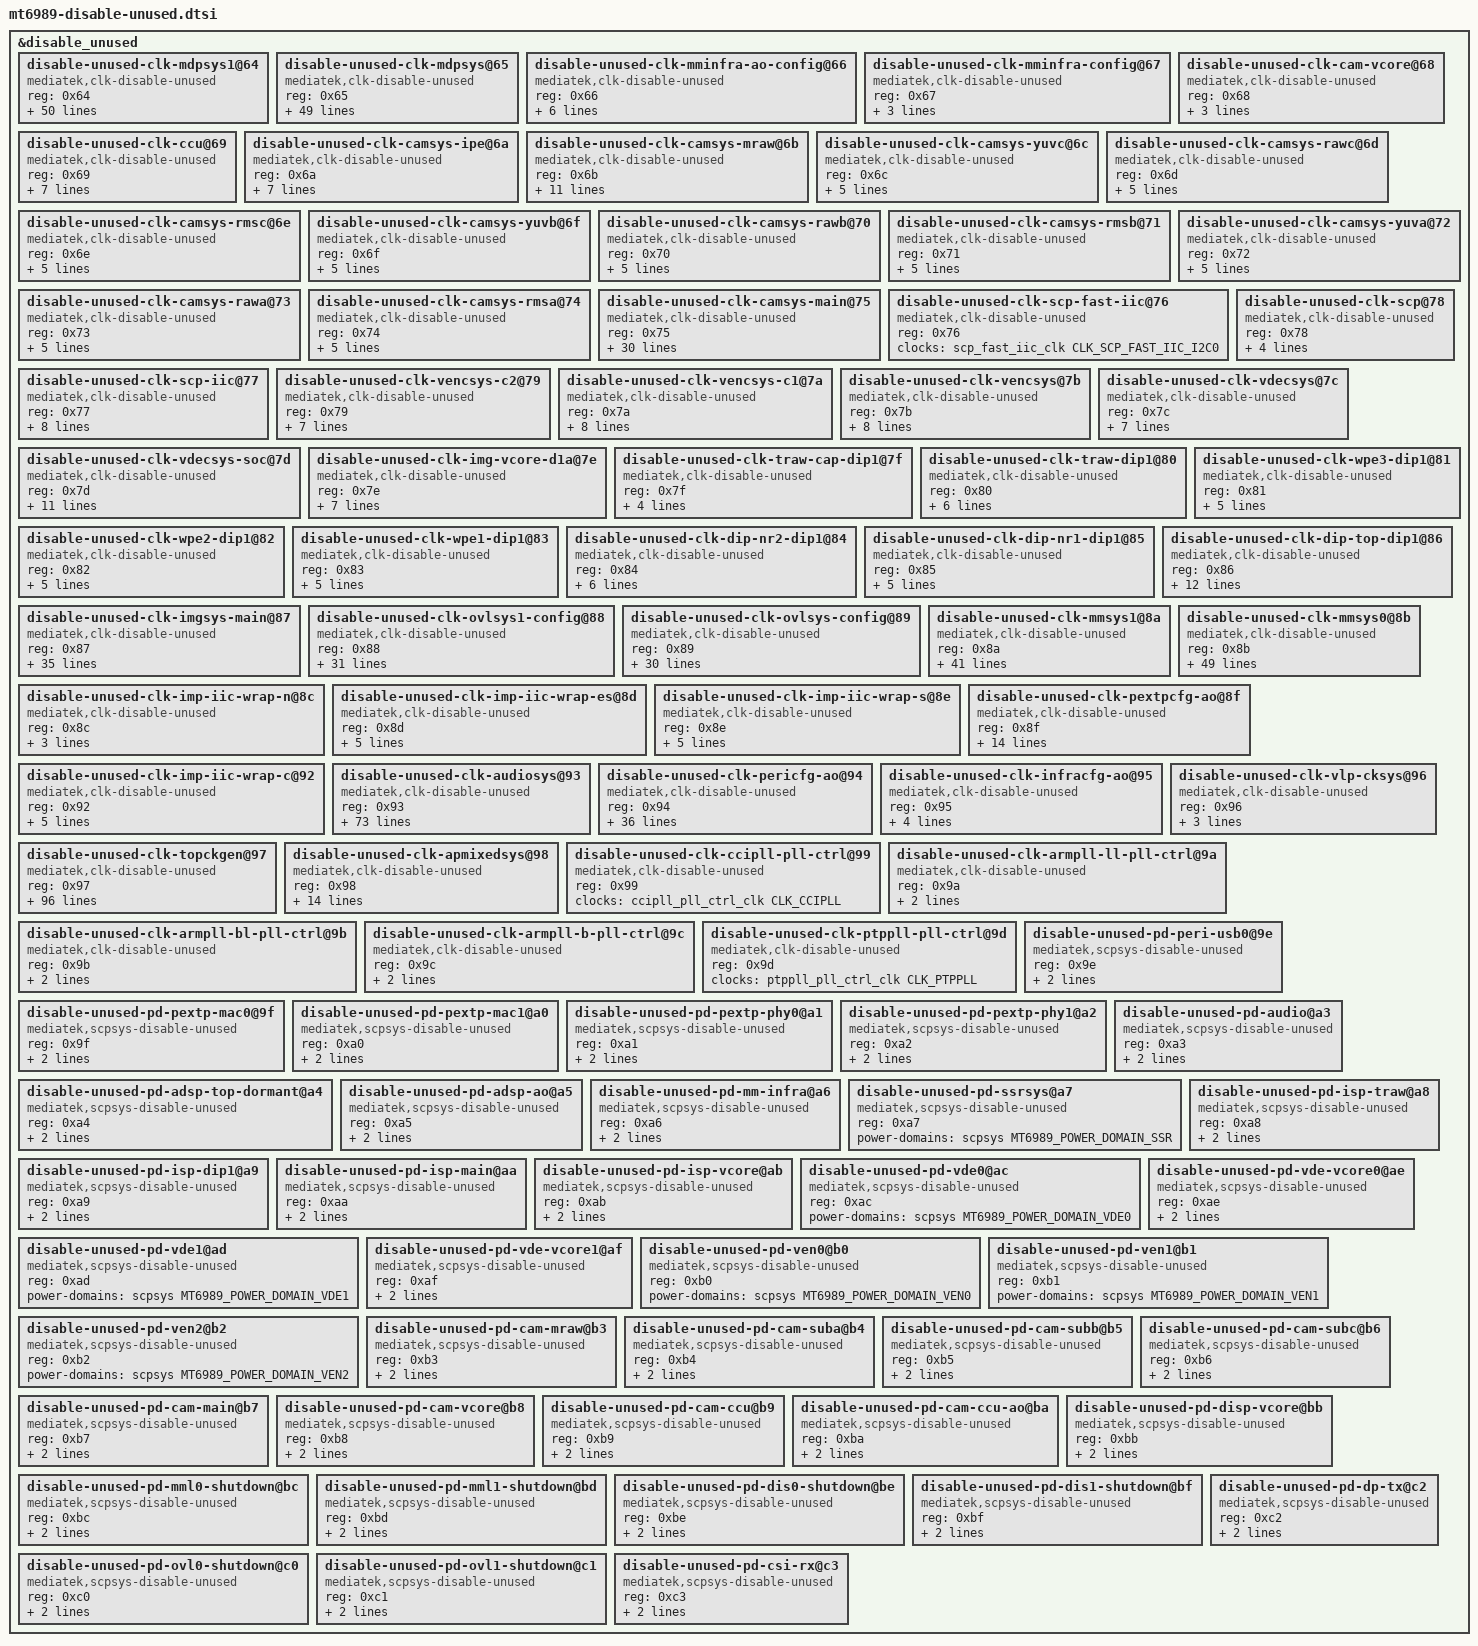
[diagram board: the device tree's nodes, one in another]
// SPDX-License-Identifier: (GPL-2.0 OR MIT)
/*
 * Copyright (C) 2023 MediaTek Inc.
 * Author: Owen Chen <owen.chen@mediatek.com>
 */

&disable_unused {
	status = "okay";
	disable-unused-clk-mdpsys1@64 {
		compatible = "mediatek,clk-disable-unused";
		reg = <0x64>;
		clocks =
			<&mdpsys1_config_clk CLK_MDP1_MDP_MUTEX0>,
			<&mdpsys1_config_clk CLK_MDP1_APB_BUS>,
			<&mdpsys1_config_clk CLK_MDP1_SMI0>,
			<&mdpsys1_config_clk CLK_MDP1_MDP_RDMA0>,
			<&mdpsys1_config_clk CLK_MDP1_MDP_RDMA2>,
			<&mdpsys1_config_clk CLK_MDP1_MDP_HDR0>,
			<&mdpsys1_config_clk CLK_MDP1_MDP_AAL0>,
			<&mdpsys1_config_clk CLK_MDP1_MDP_RSZ0>,
			<&mdpsys1_config_clk CLK_MDP1_MDP_TDSHP0>,
			<&mdpsys1_config_clk CLK_MDP1_MDP_COLOR0>,
			<&mdpsys1_config_clk CLK_MDP1_MDP_WROT0>,
			<&mdpsys1_config_clk CLK_MDP1_MDP_FAKE_ENG0>,
			<&mdpsys1_config_clk CLK_MDP1_MDP_DLI_ASYNC0>,
			<&mdpsys1_config_clk CLK_MDP1_MDP_DLI_ASYNC1>,
			<&mdpsys1_config_clk CLK_MDP1_APB_DB>,
			<&mdpsys1_config_clk CLK_MDP1_MDP_RDMA1>,
			<&mdpsys1_config_clk CLK_MDP1_MDP_RDMA3>,
			<&mdpsys1_config_clk CLK_MDP1_MDP_HDR1>,
			<&mdpsys1_config_clk CLK_MDP1_MDP_AAL1>,
			<&mdpsys1_config_clk CLK_MDP1_MDP_RSZ1>,
			<&mdpsys1_config_clk CLK_MDP1_MDP_TDSHP1>,
			<&mdpsys1_config_clk CLK_MDP1_MDP_COLOR1>,
			<&mdpsys1_config_clk CLK_MDP1_MDP_WROT1>,
			<&mdpsys1_config_clk CLK_MDP1_MDP_RSZ2>,
			<&mdpsys1_config_clk CLK_MDP1_MDP_WROT2>,
			<&mdpsys1_config_clk CLK_MDP1_MDP_DLO_ASYNC0>,
			<&mdpsys1_config_clk CLK_MDP1_MDP_RSZ3>,
			<&mdpsys1_config_clk CLK_MDP1_MDP_WROT3>,
			<&mdpsys1_config_clk CLK_MDP1_MDP_DLO_ASYNC1>,
			<&mdpsys1_config_clk CLK_MDP1_MDP_DLI_ASYNC2>,
			<&mdpsys1_config_clk CLK_MDP1_MDP_DLI_ASYNC3>,
			<&mdpsys1_config_clk CLK_MDP1_MDP_DLO_ASYNC2>,
			<&mdpsys1_config_clk CLK_MDP1_MDP_DLO_ASYNC3>,
			<&mdpsys1_config_clk CLK_MDP1_MDP_BIRSZ0>,
			<&mdpsys1_config_clk CLK_MDP1_MDP_BIRSZ1>,
			<&mdpsys1_config_clk CLK_MDP1_IMG_DL_ASYNC0>,
			<&mdpsys1_config_clk CLK_MDP1_IMG_DL_ASYNC1>,
			<&mdpsys1_config_clk CLK_MDP1_HRE_TOP_MDPSYS>,
			<&mdpsys1_config_clk CLK_MDP1_MDP_RROT0>,
			<&mdpsys1_config_clk CLK_MDP1_MDP_RROT0_2ND>,
			<&mdpsys1_config_clk CLK_MDP1_MDP_MERGE0>,
			<&mdpsys1_config_clk CLK_MDP1_MDP_C3D0>,
			<&mdpsys1_config_clk CLK_MDP1_MDP_FG0>,
			<&mdpsys1_config_clk CLK_MDP1_IMG_DL_RELAY0>,
			<&mdpsys1_config_clk CLK_MDP1_F26M_SLOW>,
			<&mdpsys1_config_clk CLK_MDP1_F32K_SLOW>,
			<&mdpsys1_config_clk CLK_MDP1_IMG_DL_RELAY1>;
		power-domains = <&scpsys MT6989_POWER_DOMAIN_MML1_SHUTDOWN>;
	};

	disable-unused-clk-mdpsys@65 {
		compatible = "mediatek,clk-disable-unused";
		reg = <0x65>;
		clocks =
			<&mdpsys_config_clk CLK_MDP_MUTEX0>,
			<&mdpsys_config_clk CLK_MDP_APB_BUS>,
			<&mdpsys_config_clk CLK_MDP_SMI0>,
			<&mdpsys_config_clk CLK_MDP_RDMA0>,
			<&mdpsys_config_clk CLK_MDP_RDMA2>,
			<&mdpsys_config_clk CLK_MDP_HDR0>,
			<&mdpsys_config_clk CLK_MDP_AAL0>,
			<&mdpsys_config_clk CLK_MDP_RSZ0>,
			<&mdpsys_config_clk CLK_MDP_TDSHP0>,
			<&mdpsys_config_clk CLK_MDP_COLOR0>,
			<&mdpsys_config_clk CLK_MDP_WROT0>,
			<&mdpsys_config_clk CLK_MDP_FAKE_ENG0>,
			<&mdpsys_config_clk CLK_MDP_DLI_ASYNC0>,
			<&mdpsys_config_clk CLK_MDP_DLI_ASYNC1>,
			<&mdpsys_config_clk CLK_MDP_APB_DB>,
			<&mdpsys_config_clk CLK_MDP_RDMA1>,
			<&mdpsys_config_clk CLK_MDP_RDMA3>,
			<&mdpsys_config_clk CLK_MDP_HDR1>,
			<&mdpsys_config_clk CLK_MDP_AAL1>,
			<&mdpsys_config_clk CLK_MDP_RSZ1>,
			<&mdpsys_config_clk CLK_MDP_TDSHP1>,
			<&mdpsys_config_clk CLK_MDP_COLOR1>,
			<&mdpsys_config_clk CLK_MDP_WROT1>,
			<&mdpsys_config_clk CLK_MDP_RSZ2>,
			<&mdpsys_config_clk CLK_MDP_WROT2>,
			<&mdpsys_config_clk CLK_MDP_DLO_ASYNC0>,
			<&mdpsys_config_clk CLK_MDP_RSZ3>,
			<&mdpsys_config_clk CLK_MDP_WROT3>,
			<&mdpsys_config_clk CLK_MDP_DLO_ASYNC1>,
			<&mdpsys_config_clk CLK_MDP_DLI_ASYNC2>,
			<&mdpsys_config_clk CLK_MDP_DLI_ASYNC3>,
			<&mdpsys_config_clk CLK_MDP_DLO_ASYNC2>,
			<&mdpsys_config_clk CLK_MDP_DLO_ASYNC3>,
			<&mdpsys_config_clk CLK_MDP_BIRSZ0>,
			<&mdpsys_config_clk CLK_MDP_BIRSZ1>,
			<&mdpsys_config_clk CLK_MDP_IMG_DL_ASYNC0>,
			<&mdpsys_config_clk CLK_MDP_IMG_DL_ASYNC1>,
			<&mdpsys_config_clk CLK_MDP_HRE_TOP_MDPSYS>,
			<&mdpsys_config_clk CLK_MDP_RROT0>,
			<&mdpsys_config_clk CLK_MDP_RROT0_2ND>,
			<&mdpsys_config_clk CLK_MDP_MERGE0>,
			<&mdpsys_config_clk CLK_MDP_C3D0>,
			<&mdpsys_config_clk CLK_MDP_FG0>,
			<&mdpsys_config_clk CLK_MDP_IMG_DL_RELAY0>,
			<&mdpsys_config_clk CLK_MDP_F26M_SLOW>,
			<&mdpsys_config_clk CLK_MDP_F32K_SLOW>,
			<&mdpsys_config_clk CLK_MDP_IMG_DL_RELAY1>;
		power-domains = <&scpsys MT6989_POWER_DOMAIN_MML0_SHUTDOWN>;
	};

	disable-unused-clk-mminfra-ao-config@66 {
		compatible = "mediatek,clk-disable-unused";
		reg = <0x66>;
		clocks =
			<&mminfra_ao_config_clk CLK_MMINFRA_AO_GCE_D>,
			<&mminfra_ao_config_clk CLK_MMINFRA_AO_GCE_M>,
			<&mminfra_ao_config_clk CLK_MMINFRA_AO_GCE_26M>;
		power-domains = <&scpsys MT6989_POWER_DOMAIN_MM_INFRA>;
	};

	disable-unused-clk-mminfra-config@67 {
		compatible = "mediatek,clk-disable-unused";
		reg = <0x67>;
		clocks =
			<&mminfra_config_clk CLK_MMINFRA_SMI>;
		power-domains = <&scpsys MT6989_POWER_DOMAIN_MM_INFRA>;
	};

	disable-unused-clk-cam-vcore@68 {
		compatible = "mediatek,clk-disable-unused";
		reg = <0x68>;
		clocks =
			<&cam_vcore_clk CLK_CAM_V_MM0_SUBCOMM>;
		power-domains = <&scpsys MT6989_POWER_DOMAIN_CAM_MAIN>;
	};

	disable-unused-clk-ccu@69 {
		compatible = "mediatek,clk-disable-unused";
		reg = <0x69>;
		clocks =
			<&ccu_main_clk CLK_CCU_LARB30_CON>,
			<&ccu_main_clk CLK_CCU_AHB_CON>,
			<&ccu_main_clk CLK_CCUSYS_CCU0_CON>,
			<&ccu_main_clk CLK_CCUSYS_CCU1_CON>,
			<&ccu_main_clk CLK_CCU2MM0_GALS_CON>;
		power-domains = <&scpsys MT6989_POWER_DOMAIN_CAM_CCU>;
	};

	disable-unused-clk-camsys-ipe@6a {
		compatible = "mediatek,clk-disable-unused";
		reg = <0x6a>;
		clocks =
			<&camsys_ipe_clk CLK_CAMSYS_IPE_LARB19>,
			<&camsys_ipe_clk CLK_CAMSYS_IPE_DPE>,
			<&camsys_ipe_clk CLK_CAMSYS_IPE_FUS>,
			<&camsys_ipe_clk CLK_CAMSYS_IPE_DHZE>,
			<&camsys_ipe_clk CLK_CAMSYS_IPE_GALS>;
		power-domains = <&scpsys MT6989_POWER_DOMAIN_CAM_MRAW>;
	};

	disable-unused-clk-camsys-mraw@6b {
		compatible = "mediatek,clk-disable-unused";
		reg = <0x6b>;
		clocks =
			<&camsys_mraw_clk CLK_CAM_MR_LARBX>,
			<&camsys_mraw_clk CLK_CAM_MR_GALS>,
			<&camsys_mraw_clk CLK_CAM_MR_CAMTG>,
			<&camsys_mraw_clk CLK_CAM_MR_MRAW0>,
			<&camsys_mraw_clk CLK_CAM_MR_MRAW1>,
			<&camsys_mraw_clk CLK_CAM_MR_MRAW2>,
			<&camsys_mraw_clk CLK_CAM_MR_MRAW3>,
			<&camsys_mraw_clk CLK_CAM_MR_PDA0>,
			<&camsys_mraw_clk CLK_CAM_MR_PDA1>;
		power-domains = <&scpsys MT6989_POWER_DOMAIN_CAM_MRAW>;
	};

	disable-unused-clk-camsys-yuvc@6c {
		compatible = "mediatek,clk-disable-unused";
		reg = <0x6c>;
		clocks =
			<&camsys_yuvc_clk CLK_CAM_YC_LARBX>,
			<&camsys_yuvc_clk CLK_CAM_YC_CAM>,
			<&camsys_yuvc_clk CLK_CAM_YC_CAMTG>;
		power-domains = <&scpsys MT6989_POWER_DOMAIN_CAM_SUBC>;
	};

	disable-unused-clk-camsys-rawc@6d {
		compatible = "mediatek,clk-disable-unused";
		reg = <0x6d>;
		clocks =
			<&camsys_rawc_clk CLK_CAM_RC_LARBX>,
			<&camsys_rawc_clk CLK_CAM_RC_CAM>,
			<&camsys_rawc_clk CLK_CAM_RC_CAMTG>;
		power-domains = <&scpsys MT6989_POWER_DOMAIN_CAM_SUBC>;
	};

	disable-unused-clk-camsys-rmsc@6e {
		compatible = "mediatek,clk-disable-unused";
		reg = <0x6e>;
		clocks =
			<&camsys_rmsc_clk CLK_CAMSYS_RMSC_LARBX>,
			<&camsys_rmsc_clk CLK_CAMSYS_RMSC_CAM>,
			<&camsys_rmsc_clk CLK_CAMSYS_RMSC_CAMTG>;
		power-domains = <&scpsys MT6989_POWER_DOMAIN_CAM_SUBC>;
	};

	disable-unused-clk-camsys-yuvb@6f {
		compatible = "mediatek,clk-disable-unused";
		reg = <0x6f>;
		clocks =
			<&camsys_yuvb_clk CLK_CAM_YB_LARBX>,
			<&camsys_yuvb_clk CLK_CAM_YB_CAM>,
			<&camsys_yuvb_clk CLK_CAM_YB_CAMTG>;
		power-domains = <&scpsys MT6989_POWER_DOMAIN_CAM_SUBB>;
	};

	disable-unused-clk-camsys-rawb@70 {
		compatible = "mediatek,clk-disable-unused";
		reg = <0x70>;
		clocks =
			<&camsys_rawb_clk CLK_CAM_RB_LARBX>,
			<&camsys_rawb_clk CLK_CAM_RB_CAM>,
			<&camsys_rawb_clk CLK_CAM_RB_CAMTG>;
		power-domains = <&scpsys MT6989_POWER_DOMAIN_CAM_SUBB>;
	};

	disable-unused-clk-camsys-rmsb@71 {
		compatible = "mediatek,clk-disable-unused";
		reg = <0x71>;
		clocks =
			<&camsys_rmsb_clk CLK_CAMSYS_RMSB_LARBX>,
			<&camsys_rmsb_clk CLK_CAMSYS_RMSB_CAM>,
			<&camsys_rmsb_clk CLK_CAMSYS_RMSB_CAMTG>;
		power-domains = <&scpsys MT6989_POWER_DOMAIN_CAM_SUBB>;
	};

	disable-unused-clk-camsys-yuva@72 {
		compatible = "mediatek,clk-disable-unused";
		reg = <0x72>;
		clocks =
			<&camsys_yuva_clk CLK_CAM_YA_LARBX>,
			<&camsys_yuva_clk CLK_CAM_YA_CAM>,
			<&camsys_yuva_clk CLK_CAM_YA_CAMTG>;
		power-domains = <&scpsys MT6989_POWER_DOMAIN_CAM_SUBA>;
	};

	disable-unused-clk-camsys-rawa@73 {
		compatible = "mediatek,clk-disable-unused";
		reg = <0x73>;
		clocks =
			<&camsys_rawa_clk CLK_CAM_RA_LARBX>,
			<&camsys_rawa_clk CLK_CAM_RA_CAM>,
			<&camsys_rawa_clk CLK_CAM_RA_CAMTG>;
		power-domains = <&scpsys MT6989_POWER_DOMAIN_CAM_SUBA>;
	};

	disable-unused-clk-camsys-rmsa@74 {
		compatible = "mediatek,clk-disable-unused";
		reg = <0x74>;
		clocks =
			<&camsys_rmsa_clk CLK_CAMSYS_RMSA_LARBX>,
			<&camsys_rmsa_clk CLK_CAMSYS_RMSA_CAM>,
			<&camsys_rmsa_clk CLK_CAMSYS_RMSA_CAMTG>;
		power-domains = <&scpsys MT6989_POWER_DOMAIN_CAM_SUBA>;
	};

	disable-unused-clk-camsys-main@75 {
		compatible = "mediatek,clk-disable-unused";
		reg = <0x75>;
		clocks =
			<&camsys_main_clk CLK_CAM_MAIN_LARB13>,
			<&camsys_main_clk CLK_CAM_MAIN_LARB14>,
			<&camsys_main_clk CLK_CAM_MAIN_LARB27>,
			<&camsys_main_clk CLK_CAM_MAIN_LARB29>,
			<&camsys_main_clk CLK_CAM_MAIN_CAM>,
			<&camsys_main_clk CLK_CAM_MAIN_CAM_SUBA>,
			<&camsys_main_clk CLK_CAM_MAIN_CAM_SUBB>,
			<&camsys_main_clk CLK_CAM_MAIN_CAM_SUBC>,
			<&camsys_main_clk CLK_CAM_MAIN_CAM_MRAW>,
			<&camsys_main_clk CLK_CAM_MAIN_CAMTG>,
			<&camsys_main_clk CLK_CAM_MAIN_SENINF>,
			<&camsys_main_clk CLK_CAM_MAIN_CAMSV_TOP>,
			<&camsys_main_clk CLK_CAM_MAIN_ADLRD>,
			<&camsys_main_clk CLK_CAM_MAIN_ADLWR>,
			<&camsys_main_clk CLK_CAM_MAIN_UISP>,
			<&camsys_main_clk CLK_CAM_MAIN_CAM2MM0_GALS>,
			<&camsys_main_clk CLK_CAM_MAIN_CAM2MM1_GALS>,
			<&camsys_main_clk CLK_CAM_MAIN_CAM2SYS_GALS>,
			<&camsys_main_clk CLK_CAM_MAIN_CAM2MM2_GALS>,
			<&camsys_main_clk CLK_CAM_MAIN_CCUSYS>,
			<&camsys_main_clk CLK_CAM_MAIN_CAM_DPE>,
			<&camsys_main_clk CLK_CAM_MAIN_CAM_ASG>,
			<&camsys_main_clk CLK_CAM_MAIN_CAMSV_A_CON_1>,
			<&camsys_main_clk CLK_CAM_MAIN_CAMSV_B_CON_1>,
			<&camsys_main_clk CLK_CAM_MAIN_CAMSV_C_CON_1>,
			<&camsys_main_clk CLK_CAM_MAIN_CAMSV_D_CON_1>,
			<&camsys_main_clk CLK_CAM_MAIN_CAMSV_E_CON_1>,
			<&camsys_main_clk CLK_CAM_MAIN_CAMSV_CON_1>;
		power-domains = <&scpsys MT6989_POWER_DOMAIN_CAM_MAIN>;
	};

	disable-unused-clk-scp-fast-iic@76 {
		compatible = "mediatek,clk-disable-unused";
		reg = <0x76>;
		clocks =
			<&scp_fast_iic_clk CLK_SCP_FAST_IIC_I2C0>;
	};

	disable-unused-clk-scp-iic@77 {
		compatible = "mediatek,clk-disable-unused";
		reg = <0x77>;
		clocks =
			<&scp_iic_clk CLK_SCP_IIC_I2C0>,
			<&scp_iic_clk CLK_SCP_IIC_I2C1>,
			<&scp_iic_clk CLK_SCP_IIC_I2C2>,
			<&scp_iic_clk CLK_SCP_IIC_I2C3>,
			<&scp_iic_clk CLK_SCP_IIC_I2C4>,
			<&scp_iic_clk CLK_SCP_IIC_I2C5>,
			<&scp_iic_clk CLK_SCP_IIC_I2C6>,
			<&scp_iic_clk CLK_SCP_IIC_I2C7>;
	};

	disable-unused-clk-scp@78 {
		compatible = "mediatek,clk-disable-unused";
		reg = <0x78>;
		clocks =
			<&scp_clk CLK_SCP_SET_SPI0>,
			<&scp_clk CLK_SCP_SET_SPI1>,
			<&scp_clk CLK_SCP_SET_SPI2>,
			<&scp_clk CLK_SCP_SET_SPI3>;
	};

	disable-unused-clk-vencsys-c2@79 {
		compatible = "mediatek,clk-disable-unused";
		reg = <0x79>;
		clocks =
			<&venc_gcon_core2_clk CLK_VEN_C2_CKE0_LARB>,
			<&venc_gcon_core2_clk CLK_VEN_C2_CKE1_VENC>,
			<&venc_gcon_core2_clk CLK_VEN_C2_CKE2_JPGENC>,
			<&venc_gcon_core2_clk CLK_VEN_C2_CKE5_GALS>,
			<&venc_gcon_core2_clk CLK_VEN_C2_CKE6_GALS_SRAM>;
		power-domains = <&scpsys MT6989_POWER_DOMAIN_VEN2>;
	};

	disable-unused-clk-vencsys-c1@7a {
		compatible = "mediatek,clk-disable-unused";
		reg = <0x7a>;
		clocks =
			<&venc_gcon_core1_clk CLK_VEN2_CKE0_LARB>,
			<&venc_gcon_core1_clk CLK_VEN2_CKE1_VENC>,
			<&venc_gcon_core1_clk CLK_VEN2_CKE2_JPGENC>,
			<&venc_gcon_core1_clk CLK_VEN2_CKE3_JPGDEC>,
			<&venc_gcon_core1_clk CLK_VEN2_CKE5_GALS>,
			<&venc_gcon_core1_clk CLK_VEN2_CKE6_GALS_SRAM>;
		power-domains = <&scpsys MT6989_POWER_DOMAIN_VEN1>;
	};

	disable-unused-clk-vencsys@7b {
		compatible = "mediatek,clk-disable-unused";
		reg = <0x7b>;
		clocks =
			<&venc_gcon_clk CLK_VEN1_CKE0_LARB>,
			<&venc_gcon_clk CLK_VEN1_CKE1_VENC>,
			<&venc_gcon_clk CLK_VEN1_CKE2_JPGENC>,
			<&venc_gcon_clk CLK_VEN1_CKE3_JPGDEC>,
			<&venc_gcon_clk CLK_VEN1_CKE4_JPGDEC_C1>,
			<&venc_gcon_clk CLK_VEN1_CKE5_GALS>,
			<&venc_gcon_clk CLK_VEN1_CKE6_GALS_SRAM>;
		power-domains = <&scpsys MT6989_POWER_DOMAIN_VEN0>;
	};

	disable-unused-clk-vdecsys@7c {
		compatible = "mediatek,clk-disable-unused";
		reg = <0x7c>;
		clocks =
			<&vdec_gcon_base_clk CLK_VDE2_LAT_CKEN>,
			<&vdec_gcon_base_clk CLK_VDE2_LAT_ACTIVE>,
			<&vdec_gcon_base_clk CLK_VDE2_LAT_CKEN_ENG>,
			<&vdec_gcon_base_clk CLK_VDE2_VDEC_CKEN>,
			<&vdec_gcon_base_clk CLK_VDE2_VDEC_ACTIVE>,
			<&vdec_gcon_base_clk CLK_VDE2_VDEC_CKEN_ENG>;
		power-domains = <&scpsys MT6989_POWER_DOMAIN_VDE1>;
	};

	disable-unused-clk-vdecsys-soc@7d {
		compatible = "mediatek,clk-disable-unused";
		reg = <0x7d>;
		clocks =
			<&vdec_soc_gcon_base_clk CLK_VDE1_LAT_CKEN>,
			<&vdec_soc_gcon_base_clk CLK_VDE1_LAT_ACTIVE>,
			<&vdec_soc_gcon_base_clk CLK_VDE1_LAT_CKEN_ENG>,
			<&vdec_soc_gcon_base_clk CLK_VDE1_VDEC_CKEN>,
			<&vdec_soc_gcon_base_clk CLK_VDE1_VDEC_ACTIVE>,
			<&vdec_soc_gcon_base_clk CLK_VDE1_VDEC_CKEN_ENG>,
			<&vdec_soc_gcon_base_clk CLK_VDE1_VDEC_SOC_APTV_EN>,
			<&vdec_soc_gcon_base_clk CLK_VDE1_VDEC_SOC_APTV_TOP_EN>,
			<&vdec_soc_gcon_base_clk CLK_VDE1_VDEC_SOC_IPS_EN>;
		power-domains = <&scpsys MT6989_POWER_DOMAIN_VDE0>;
	};

	disable-unused-clk-img-vcore-d1a@7e {
		compatible = "mediatek,clk-disable-unused";
		reg = <0x7e>;
		clocks =
			<&img_vcore_d1a_clk CLK_IMG_VCORE_GALS_DISP>,
			<&img_vcore_d1a_clk CLK_IMG_VCORE_MAIN>,
			<&img_vcore_d1a_clk CLK_IMG_VCORE_SUB0>,
			<&img_vcore_d1a_clk CLK_IMG_VCORE_SUB1>;
		power-domains = <&scpsys MT6989_POWER_DOMAIN_ISP_MAIN>;
	};

	disable-unused-clk-traw-cap-dip1@7f {
		compatible = "mediatek,clk-disable-unused";
		reg = <0x7f>;
		clocks =
			<&traw_cap_dip1_clk CLK_TRAW_CAP_DIP1_TRAW_CAP>;
		power-domains = <&scpsys MT6989_POWER_DOMAIN_ISP_DIP1>;
	};

	disable-unused-clk-traw-dip1@80 {
		compatible = "mediatek,clk-disable-unused";
		reg = <0x80>;
		clocks =
			<&traw_dip1_clk CLK_TRAW_DIP1_LARB28>,
			<&traw_dip1_clk CLK_TRAW_DIP1_LARB40>,
			<&traw_dip1_clk CLK_TRAW_DIP1_TRAW>,
			<&traw_dip1_clk CLK_TRAW_DIP1_GALS>;
		power-domains = <&scpsys MT6989_POWER_DOMAIN_ISP_DIP1>;
	};

	disable-unused-clk-wpe3-dip1@81 {
		compatible = "mediatek,clk-disable-unused";
		reg = <0x81>;
		clocks =
			<&wpe3_dip1_clk CLK_WPE3_DIP1_LARB11>,
			<&wpe3_dip1_clk CLK_WPE3_DIP1_WPE>,
			<&wpe3_dip1_clk CLK_WPE3_DIP1_GALS0>;
		power-domains = <&scpsys MT6989_POWER_DOMAIN_ISP_DIP1>;
	};

	disable-unused-clk-wpe2-dip1@82 {
		compatible = "mediatek,clk-disable-unused";
		reg = <0x82>;
		clocks =
			<&wpe2_dip1_clk CLK_WPE2_DIP1_LARB11>,
			<&wpe2_dip1_clk CLK_WPE2_DIP1_WPE>,
			<&wpe2_dip1_clk CLK_WPE2_DIP1_GALS0>;
		power-domains = <&scpsys MT6989_POWER_DOMAIN_ISP_DIP1>;
	};

	disable-unused-clk-wpe1-dip1@83 {
		compatible = "mediatek,clk-disable-unused";
		reg = <0x83>;
		clocks =
			<&wpe1_dip1_clk CLK_WPE1_DIP1_LARB11>,
			<&wpe1_dip1_clk CLK_WPE1_DIP1_WPE>,
			<&wpe1_dip1_clk CLK_WPE1_DIP1_GALS0>;
		power-domains = <&scpsys MT6989_POWER_DOMAIN_ISP_DIP1>;
	};

	disable-unused-clk-dip-nr2-dip1@84 {
		compatible = "mediatek,clk-disable-unused";
		reg = <0x84>;
		clocks =
			<&dip_nr2_dip1_clk CLK_DIP_NR2_DIP1_LARB15>,
			<&dip_nr2_dip1_clk CLK_DIP_NR2_DIP1_DIP_NR>,
			<&dip_nr2_dip1_clk CLK_DIP_NR2_DIP1_LARB39>;
		power-domains = <&scpsys MT6989_POWER_DOMAIN_ISP_DIP1>;
	};

	disable-unused-clk-dip-nr1-dip1@85 {
		compatible = "mediatek,clk-disable-unused";
		reg = <0x85>;
		clocks =
			<&dip_nr1_dip1_clk CLK_DIP_NR1_DIP1_LARB>,
			<&dip_nr1_dip1_clk CLK_DIP_NR1_DIP1_DIP_NR1>;
		power-domains = <&scpsys MT6989_POWER_DOMAIN_ISP_DIP1>;
	};

	disable-unused-clk-dip-top-dip1@86 {
		compatible = "mediatek,clk-disable-unused";
		reg = <0x86>;
		clocks =
			<&dip_top_dip1_clk CLK_DIP_TOP_DIP1_DIP_TOP>,
			<&dip_top_dip1_clk CLK_DIP_TOP_DIP1_DIP_TOP_GALS0>,
			<&dip_top_dip1_clk CLK_DIP_TOP_DIP1_DIP_TOP_GALS1>,
			<&dip_top_dip1_clk CLK_DIP_TOP_DIP1_DIP_TOP_GALS2>,
			<&dip_top_dip1_clk CLK_DIP_TOP_DIP1_DIP_TOP_GALS3>,
			<&dip_top_dip1_clk CLK_DIP_TOP_DIP1_LARB10>,
			<&dip_top_dip1_clk CLK_DIP_TOP_DIP1_LARB15>,
			<&dip_top_dip1_clk CLK_DIP_TOP_DIP1_LARB38>,
			<&dip_top_dip1_clk CLK_DIP_TOP_DIP1_LARB39>;
		power-domains = <&scpsys MT6989_POWER_DOMAIN_ISP_DIP1>;
	};

	disable-unused-clk-imgsys-main@87 {
		compatible = "mediatek,clk-disable-unused";
		reg = <0x87>;
		clocks =
			<&imgsys_main_clk CLK_IMG_FDVT>,
			<&imgsys_main_clk CLK_IMG_ME>,
			<&imgsys_main_clk CLK_IMG_MMG>,
			<&imgsys_main_clk CLK_IMG_LARB12>,
			<&imgsys_main_clk CLK_IMG_LARB9>,
			<&imgsys_main_clk CLK_IMG_TRAW0>,
			<&imgsys_main_clk CLK_IMG_TRAW1>,
			<&imgsys_main_clk CLK_IMG_DIP0>,
			<&imgsys_main_clk CLK_IMG_WPE0>,
			<&imgsys_main_clk CLK_IMG_IPE>,
			<&imgsys_main_clk CLK_IMG_WPE1>,
			<&imgsys_main_clk CLK_IMG_WPE2>,
			<&imgsys_main_clk CLK_IMG_ADL_LARB>,
			<&imgsys_main_clk CLK_IMG_ADLRD>,
			<&imgsys_main_clk CLK_IMG_ADLWR>,
			<&imgsys_main_clk CLK_IMG_AVS>,
			<&imgsys_main_clk CLK_IMG_IPS>,
			<&imgsys_main_clk CLK_IMG_SUB_COMMON0>,
			<&imgsys_main_clk CLK_IMG_SUB_COMMON1>,
			<&imgsys_main_clk CLK_IMG_SUB_COMMON2>,
			<&imgsys_main_clk CLK_IMG_SUB_COMMON3>,
			<&imgsys_main_clk CLK_IMG_SUB_COMMON4>,
			<&imgsys_main_clk CLK_IMG_GALS_RX_DIP0>,
			<&imgsys_main_clk CLK_IMG_GALS_RX_DIP1>,
			<&imgsys_main_clk CLK_IMG_GALS_RX_TRAW0>,
			<&imgsys_main_clk CLK_IMG_GALS_RX_WPE0>,
			<&imgsys_main_clk CLK_IMG_GALS_RX_WPE1>,
			<&imgsys_main_clk CLK_IMG_GALS_RX_WPE2>,
			<&imgsys_main_clk CLK_IMG_GALS_RX_IPE0>,
			<&imgsys_main_clk CLK_IMG_GALS_TX_IPE0>,
			<&imgsys_main_clk CLK_IMG_GALS_RX_IPE1>,
			<&imgsys_main_clk CLK_IMG_GALS_TX_IPE1>,
			<&imgsys_main_clk CLK_IMG_GALS>;
		power-domains = <&scpsys MT6989_POWER_DOMAIN_ISP_MAIN>;
	};

	disable-unused-clk-ovlsys1-config@88 {
		compatible = "mediatek,clk-disable-unused";
		reg = <0x88>;
		clocks =
			<&ovlsys1_config_clk CLK_OVL1_OVLSYS_CONFIG>,
			<&ovlsys1_config_clk CLK_OVL1_DISP_FAKE_ENG0>,
			<&ovlsys1_config_clk CLK_OVL1_DISP_FAKE_ENG1>,
			<&ovlsys1_config_clk CLK_OVL1_DISP_MUTEX0>,
			<&ovlsys1_config_clk CLK_OVL1_DISP_OVL0_2L>,
			<&ovlsys1_config_clk CLK_OVL1_DISP_OVL1_2L>,
			<&ovlsys1_config_clk CLK_OVL1_DISP_OVL2_2L>,
			<&ovlsys1_config_clk CLK_OVL1_DISP_OVL3_2L>,
			<&ovlsys1_config_clk CLK_OVL1_DISP_RSZ1>,
			<&ovlsys1_config_clk CLK_OVL1_MDP_RSZ0>,
			<&ovlsys1_config_clk CLK_OVL1_DISP_WDMA0>,
			<&ovlsys1_config_clk CLK_OVL1_DISP_UFBC_WDMA0>,
			<&ovlsys1_config_clk CLK_OVL1_DISP_WDMA2>,
			<&ovlsys1_config_clk CLK_OVL1_DISP_DLI_ASYNC0>,
			<&ovlsys1_config_clk CLK_OVL1_DISP_DLI_ASYNC1>,
			<&ovlsys1_config_clk CLK_OVL1_DISP_DLI_ASYNC2>,
			<&ovlsys1_config_clk CLK_OVL1_DISP_DL0_ASYNC0>,
			<&ovlsys1_config_clk CLK_OVL1_DISP_DL0_ASYNC1>,
			<&ovlsys1_config_clk CLK_OVL1_DISP_DL0_ASYNC2>,
			<&ovlsys1_config_clk CLK_OVL1_DISP_DL0_ASYNC3>,
			<&ovlsys1_config_clk CLK_OVL1_DISP_DL0_ASYNC4>,
			<&ovlsys1_config_clk CLK_OVL1_DISP_DL0_ASYNC5>,
			<&ovlsys1_config_clk CLK_OVL1_DISP_DL0_ASYNC6>,
			<&ovlsys1_config_clk CLK_OVL1_INLINEROT0>,
			<&ovlsys1_config_clk CLK_OVL1_SMI_SUB_COMM0>,
			<&ovlsys1_config_clk CLK_OVL1_DISP_Y2R0>,
			<&ovlsys1_config_clk CLK_OVL1_DISP_Y2R1>,
			<&ovlsys1_config_clk CLK_OVL1_DISP_OVL4_2L>;
		power-domains = <&scpsys MT6989_POWER_DOMAIN_OVL1_SHUTDOWN>;
	};

	disable-unused-clk-ovlsys-config@89 {
		compatible = "mediatek,clk-disable-unused";
		reg = <0x89>;
		clocks =
			<&ovlsys_config_clk CLK_OVLSYS_CONFIG>,
			<&ovlsys_config_clk CLK_OVL_DISP_FAKE_ENG0>,
			<&ovlsys_config_clk CLK_OVL_DISP_FAKE_ENG1>,
			<&ovlsys_config_clk CLK_OVL_DISP_MUTEX0>,
			<&ovlsys_config_clk CLK_OVL_DISP_OVL0_2L>,
			<&ovlsys_config_clk CLK_OVL_DISP_OVL1_2L>,
			<&ovlsys_config_clk CLK_OVL_DISP_OVL2_2L>,
			<&ovlsys_config_clk CLK_OVL_DISP_OVL3_2L>,
			<&ovlsys_config_clk CLK_OVL_DISP_RSZ1>,
			<&ovlsys_config_clk CLK_OVL_MDP_RSZ0>,
			<&ovlsys_config_clk CLK_OVL_DISP_WDMA0>,
			<&ovlsys_config_clk CLK_OVL_DISP_UFBC_WDMA0>,
			<&ovlsys_config_clk CLK_OVL_DISP_WDMA2>,
			<&ovlsys_config_clk CLK_OVL_DISP_DLI_ASYNC0>,
			<&ovlsys_config_clk CLK_OVL_DISP_DLI_ASYNC1>,
			<&ovlsys_config_clk CLK_OVL_DISP_DLI_ASYNC2>,
			<&ovlsys_config_clk CLK_OVL_DISP_DL0_ASYNC0>,
			<&ovlsys_config_clk CLK_OVL_DISP_DL0_ASYNC1>,
			<&ovlsys_config_clk CLK_OVL_DISP_DL0_ASYNC2>,
			<&ovlsys_config_clk CLK_OVL_DISP_DL0_ASYNC3>,
			<&ovlsys_config_clk CLK_OVL_DISP_DL0_ASYNC4>,
			<&ovlsys_config_clk CLK_OVL_DISP_DL0_ASYNC5>,
			<&ovlsys_config_clk CLK_OVL_DISP_DL0_ASYNC6>,
			<&ovlsys_config_clk CLK_OVL_INLINEROT0>,
			<&ovlsys_config_clk CLK_OVL_SMI_SUB_COMM0>,
			<&ovlsys_config_clk CLK_OVL_DISP_Y2R0>,
			<&ovlsys_config_clk CLK_OVL_DISP_Y2R1>,
			<&ovlsys_config_clk CLK_OVL_DISP_OVL4_2L>;
		power-domains = <&scpsys MT6989_POWER_DOMAIN_OVL0_SHUTDOWN>;
	};

	disable-unused-clk-mmsys1@8a {
		compatible = "mediatek,clk-disable-unused";
		reg = <0x8a>;
		clocks =
			<&dispsys1_config_clk CLK_MM1_DISPSYS1_CONFIG>,
			<&dispsys1_config_clk CLK_MM1_DISP_MUTEX0>,
			<&dispsys1_config_clk CLK_MM1_DISP_DLI_ASYNC0>,
			<&dispsys1_config_clk CLK_MM1_DISP_DLI_ASYNC1>,
			<&dispsys1_config_clk CLK_MM1_DISP_DLI_ASYNC2>,
			<&dispsys1_config_clk CLK_MM1_MDP_RDMA0>,
			<&dispsys1_config_clk CLK_MM1_DISP_R2Y0>,
			<&dispsys1_config_clk CLK_MM1_DISP_SPLITTER0>,
			<&dispsys1_config_clk CLK_MM1_DISP_SPLITTER1>,
			<&dispsys1_config_clk CLK_MM1_DISP_VDCM0>,
			<&dispsys1_config_clk CLK_MM1_DISP_DSC_WRAP0>,
			<&dispsys1_config_clk CLK_MM1_DISP_DSC_WRAP1>,
			<&dispsys1_config_clk CLK_MM1_DISP_DSC_WRAP2>,
			<&dispsys1_config_clk CLK_MM1_DISP_DP_INTF0>,
			<&dispsys1_config_clk CLK_MM1_DISP_DSI0>,
			<&dispsys1_config_clk CLK_MM1_DISP_DSI1>,
			<&dispsys1_config_clk CLK_MM1_DISP_DSI2>,
			<&dispsys1_config_clk CLK_MM1_DISP_MERGE0>,
			<&dispsys1_config_clk CLK_MM1_DISP_WDMA0>,
			<&dispsys1_config_clk CLK_MM1_SMI_SUB_COMM0>,
			<&dispsys1_config_clk CLK_MM1_DISP_WDMA1>,
			<&dispsys1_config_clk CLK_MM1_DISP_WDMA2>,
			<&dispsys1_config_clk CLK_MM1_DISP_GDMA0>,
			<&dispsys1_config_clk CLK_MM1_DISP_DLI_ASYNC3>,
			<&dispsys1_config_clk CLK_MM1_DISP_DLI_ASYNC4>,
			<&dispsys1_config_clk CLK_MM1_MOD1>,
			<&dispsys1_config_clk CLK_MM1_MOD2>,
			<&dispsys1_config_clk CLK_MM1_MOD3>,
			<&dispsys1_config_clk CLK_MM1_MOD4>,
			<&dispsys1_config_clk CLK_MM1_MOD5>,
			<&dispsys1_config_clk CLK_MM1_MOD6>,
			<&dispsys1_config_clk CLK_MM1_MOD7>,
			<&dispsys1_config_clk CLK_MM1_SUBSYS>,
			<&dispsys1_config_clk CLK_MM1_DSI0>,
			<&dispsys1_config_clk CLK_MM1_DSI1>,
			<&dispsys1_config_clk CLK_MM1_DSI2>,
			<&dispsys1_config_clk CLK_MM1_DP>,
			<&dispsys1_config_clk CLK_MM1_F26M>;
		power-domains = <&scpsys MT6989_POWER_DOMAIN_DIS1_SHUTDOWN>;
	};

	disable-unused-clk-mmsys0@8b {
		compatible = "mediatek,clk-disable-unused";
		reg = <0x8b>;
		clocks =
			<&dispsys_config_clk CLK_MM_CONFIG>,
			<&dispsys_config_clk CLK_MM_DISP_MUTEX0>,
			<&dispsys_config_clk CLK_MM_DISP_AAL0>,
			<&dispsys_config_clk CLK_MM_DISP_AAL1>,
			<&dispsys_config_clk CLK_MM_DISP_C3D0>,
			<&dispsys_config_clk CLK_MM_DISP_C3D1>,
			<&dispsys_config_clk CLK_MM_DISP_CCORR0>,
			<&dispsys_config_clk CLK_MM_DISP_CCORR1>,
			<&dispsys_config_clk CLK_MM_DISP_CCORR2>,
			<&dispsys_config_clk CLK_MM_DISP_CCORR3>,
			<&dispsys_config_clk CLK_MM_DISP_CHIST0>,
			<&dispsys_config_clk CLK_MM_DISP_CHIST1>,
			<&dispsys_config_clk CLK_MM_DISP_COLOR0>,
			<&dispsys_config_clk CLK_MM_DISP_COLOR1>,
			<&dispsys_config_clk CLK_MM_DISP_DITHER0>,
			<&dispsys_config_clk CLK_MM_DISP_DITHER1>,
			<&dispsys_config_clk CLK_MM_DISP_DITHER2>,
			<&dispsys_config_clk CLK_MM_DLI_ASYNC0>,
			<&dispsys_config_clk CLK_MM_DLI_ASYNC1>,
			<&dispsys_config_clk CLK_MM_DLI_ASYNC2>,
			<&dispsys_config_clk CLK_MM_DLI_ASYNC3>,
			<&dispsys_config_clk CLK_MM_DLI_ASYNC4>,
			<&dispsys_config_clk CLK_MM_DLI_ASYNC5>,
			<&dispsys_config_clk CLK_MM_DLI_ASYNC6>,
			<&dispsys_config_clk CLK_MM_DLI_ASYNC7>,
			<&dispsys_config_clk CLK_MM_DLO_ASYNC0>,
			<&dispsys_config_clk CLK_MM_DLO_ASYNC1>,
			<&dispsys_config_clk CLK_MM_DLO_ASYNC2>,
			<&dispsys_config_clk CLK_MM_DLO_ASYNC3>,
			<&dispsys_config_clk CLK_MM_DLO_ASYNC4>,
			<&dispsys_config_clk CLK_MM_DISP_GAMMA0>,
			<&dispsys_config_clk CLK_MM_DISP_GAMMA1>,
			<&dispsys_config_clk CLK_MM_MDP_AAL0>,
			<&dispsys_config_clk CLK_MM_MDP_RDMA0>,
			<&dispsys_config_clk CLK_MM_DISP_ODDMR0>,
			<&dispsys_config_clk CLK_MM_DISP_POSTALIGN0>,
			<&dispsys_config_clk CLK_MM_DISP_POSTMASK0>,
			<&dispsys_config_clk CLK_MM_DISP_POSTMASK1>,
			<&dispsys_config_clk CLK_MM_DISP_RSZ0>,
			<&dispsys_config_clk CLK_MM_DISP_RSZ1>,
			<&dispsys_config_clk CLK_MM_DISP_SPR0>,
			<&dispsys_config_clk CLK_MM_DISP_TDSHP0>,
			<&dispsys_config_clk CLK_MM_DISP_TDSHP1>,
			<&dispsys_config_clk CLK_MM_DISP_WDMA1>,
			<&dispsys_config_clk CLK_MM_DISP_Y2R0>,
			<&dispsys_config_clk CLK_MM_MDP_AAL1>,
			<&dispsys_config_clk CLK_MM_SMI_SUB_COMM0>;
		power-domains = <&scpsys MT6989_POWER_DOMAIN_DIS0_SHUTDOWN>;
	};

	disable-unused-clk-imp-iic-wrap-n@8c {
		compatible = "mediatek,clk-disable-unused";
		reg = <0x8c>;
		clocks =
			<&imp_iic_wrap_n_clk CLK_IMPN_I2C0>,
			<&imp_iic_wrap_n_clk CLK_IMPN_I2C6>,
			<&imp_iic_wrap_n_clk CLK_IMPN_SEC_EN>;
	};

	disable-unused-clk-imp-iic-wrap-es@8d {
		compatible = "mediatek,clk-disable-unused";
		reg = <0x8d>;
		clocks =
			<&imp_iic_wrap_es_clk CLK_IMPES_I2C2>,
			<&imp_iic_wrap_es_clk CLK_IMPES_I2C4>,
			<&imp_iic_wrap_es_clk CLK_IMPES_I2C7>,
			<&imp_iic_wrap_es_clk CLK_IMPES_I2C8>,
			<&imp_iic_wrap_es_clk CLK_IMPES_SEC_EN>;
	};

	disable-unused-clk-imp-iic-wrap-s@8e {
		compatible = "mediatek,clk-disable-unused";
		reg = <0x8e>;
		clocks =
			<&imp_iic_wrap_s_clk CLK_IMPS_I2C1>,
			<&imp_iic_wrap_s_clk CLK_IMPS_I2C3>,
			<&imp_iic_wrap_s_clk CLK_IMPS_I2C5>,
			<&imp_iic_wrap_s_clk CLK_IMPS_I2C9>,
			<&imp_iic_wrap_s_clk CLK_IMPS_SEC_EN>;
	};

	disable-unused-clk-pextpcfg-ao@8f {
		compatible = "mediatek,clk-disable-unused";
		reg = <0x8f>;
		clocks =
			<&pextpcfg_ao_clk CLK_PEXTP_P0_MAC_REF>,
			<&pextpcfg_ao_clk CLK_PEXTP_P0_MAC_PL_P>,
			<&pextpcfg_ao_clk CLK_PEXTP_P0_MAC_TL>,
			<&pextpcfg_ao_clk CLK_PEXTP_P0_MAC_AXI>,
			<&pextpcfg_ao_clk CLK_PEXTP_P0_MAC_AHB_APB>,
			<&pextpcfg_ao_clk CLK_PEXTP_P0_PHY_REF>,
			<&pextpcfg_ao_clk CLK_PEXTP_P0_PHY_MCU_BUS>,
			<&pextpcfg_ao_clk CLK_PEXTP_P1_MAC_REF>,
			<&pextpcfg_ao_clk CLK_PEXTP_P1_MAC_PL_P>,
			<&pextpcfg_ao_clk CLK_PEXTP_P1_MAC_TL>,
			<&pextpcfg_ao_clk CLK_PEXTP_P1_MAC_AXI>,
			<&pextpcfg_ao_clk CLK_PEXTP_P1_MAC_AHB_APB>,
			<&pextpcfg_ao_clk CLK_PEXTP_P1_PHY_REF>,
			<&pextpcfg_ao_clk CLK_PEXTP_P1_PHY_MCU_BUS>;
	};

	disable-unused-clk-imp-iic-wrap-c@92 {
		compatible = "mediatek,clk-disable-unused";
		reg = <0x92>;
		clocks =
			<&imp_iic_wrap_c_clk CLK_IMPC_I2C10>,
			<&imp_iic_wrap_c_clk CLK_IMPC_I2C11>,
			<&imp_iic_wrap_c_clk CLK_IMPC_I2C12>,
			<&imp_iic_wrap_c_clk CLK_IMPC_I2C13>,
			<&imp_iic_wrap_c_clk CLK_IMPC_SEC_EN>;
	};

	disable-unused-clk-audiosys@93 {
		compatible = "mediatek,clk-disable-unused";
		reg = <0x93>;
		clocks =
			<&afe_clk CLK_AFE_MEMIF_INTBUS_CLK>,
			<&afe_clk CLK_AFE_MEMIF_HOP_CLK>,
			<&afe_clk CLK_AFE_PCM1>,
			<&afe_clk CLK_AFE_PCM0>,
			<&afe_clk CLK_AFE_SOUNDWIRE>,
			<&afe_clk CLK_AFE_CM1>,
			<&afe_clk CLK_AFE_CM0>,
			<&afe_clk CLK_AFE_STF>,
			<&afe_clk CLK_AFE_HW_GAIN23>,
			<&afe_clk CLK_AFE_HW_GAIN01>,
			<&afe_clk CLK_AFE_DAIBT>,
			<&afe_clk CLK_AFE_MERGE_IF>,
			<&afe_clk CLK_AFE_FM_I2S>,
			<&afe_clk CLK_AFE_UL2_ADC_HIRES_TML>,
			<&afe_clk CLK_AFE_UL2_ADC_HIRES>,
			<&afe_clk CLK_AFE_UL2_TML>,
			<&afe_clk CLK_AFE_UL2_ADC>,
			<&afe_clk CLK_AFE_UL1_ADC_HIRES_TML>,
			<&afe_clk CLK_AFE_UL1_ADC_HIRES>,
			<&afe_clk CLK_AFE_UL1_TML>,
			<&afe_clk CLK_AFE_UL1_ADC>,
			<&afe_clk CLK_AFE_UL0_ADC_HIRES_TML>,
			<&afe_clk CLK_AFE_UL0_ADC_HIRES>,
			<&afe_clk CLK_AFE_UL0_TML>,
			<&afe_clk CLK_AFE_UL0_ADC>,
			<&afe_clk CLK_AFE_DPRX>,
			<&afe_clk CLK_AFE_DPTX>,
			<&afe_clk CLK_AFE_ETDM_IN6>,
			<&afe_clk CLK_AFE_ETDM_IN5>,
			<&afe_clk CLK_AFE_ETDM_IN4>,
			<&afe_clk CLK_AFE_ETDM_IN3>,
			<&afe_clk CLK_AFE_ETDM_IN2>,
			<&afe_clk CLK_AFE_ETDM_IN1>,
			<&afe_clk CLK_AFE_ETDM_IN0>,
			<&afe_clk CLK_AFE_ETDM_OUT6>,
			<&afe_clk CLK_AFE_ETDM_OUT5>,
			<&afe_clk CLK_AFE_ETDM_OUT4>,
			<&afe_clk CLK_AFE_ETDM_OUT3>,
			<&afe_clk CLK_AFE_ETDM_OUT2>,
			<&afe_clk CLK_AFE_ETDM_OUT1>,
			<&afe_clk CLK_AFE_ETDM_OUT0>,
			<&afe_clk CLK_AFE_GENERAL24_ASRC>,
			<&afe_clk CLK_AFE_GENERAL23_ASRC>,
			<&afe_clk CLK_AFE_GENERAL22_ASRC>,
			<&afe_clk CLK_AFE_GENERAL21_ASRC>,
			<&afe_clk CLK_AFE_GENERAL20_ASRC>,
			<&afe_clk CLK_AFE_GENERAL19_ASRC>,
			<&afe_clk CLK_AFE_GENERAL18_ASRC>,
			<&afe_clk CLK_AFE_GENERAL17_ASRC>,
			<&afe_clk CLK_AFE_GENERAL16_ASRC>,
			<&afe_clk CLK_AFE_GENERAL15_ASRC>,
			<&afe_clk CLK_AFE_GENERAL14_ASRC>,
			<&afe_clk CLK_AFE_GENERAL13_ASRC>,
			<&afe_clk CLK_AFE_GENERAL12_ASRC>,
			<&afe_clk CLK_AFE_GENERAL11_ASRC>,
			<&afe_clk CLK_AFE_GENERAL10_ASRC>,
			<&afe_clk CLK_AFE_GENERAL9_ASRC>,
			<&afe_clk CLK_AFE_GENERAL8_ASRC>,
			<&afe_clk CLK_AFE_GENERAL7_ASRC>,
			<&afe_clk CLK_AFE_GENERAL6_ASRC>,
			<&afe_clk CLK_AFE_GENERAL5_ASRC>,
			<&afe_clk CLK_AFE_GENERAL4_ASRC>,
			<&afe_clk CLK_AFE_GENERAL3_ASRC>,
			<&afe_clk CLK_AFE_GENERAL2_ASRC>,
			<&afe_clk CLK_AFE_GENERAL1_ASRC>,
			<&afe_clk CLK_AFE_GENERAL0_ASRC>,
			<&afe_clk CLK_AFE_CONNSYS_I2S_ASRC>,
			<&afe_clk CLK_AFE_AUDIO_HOPPING>,
			<&afe_clk CLK_AFE_AUDIO_F26M>,
			<&afe_clk CLK_AFE_APLL1>,
			<&afe_clk CLK_AFE_APLL2>,
			<&afe_clk CLK_AFE_H208M>,
			<&afe_clk CLK_AFE_APLL_TUNER2>,
			<&afe_clk CLK_AFE_APLL_TUNER1>;
		power-domains = <&scpsys MT6989_POWER_DOMAIN_AUDIO>;
	};

	disable-unused-clk-pericfg-ao@94 {
		compatible = "mediatek,clk-disable-unused";
		reg = <0x94>;
		clocks =
			<&pericfg_ao_clk CLK_PERAOP_UART0>,
			<&pericfg_ao_clk CLK_PERAOP_UART1>,
			<&pericfg_ao_clk CLK_PERAOP_UART2>,
			<&pericfg_ao_clk CLK_PERAOP_UART3>,
			<&pericfg_ao_clk CLK_PERAOP_PWM_H>,
			<&pericfg_ao_clk CLK_PERAOP_PWM_B>,
			<&pericfg_ao_clk CLK_PERAOP_PWM_FB1>,
			<&pericfg_ao_clk CLK_PERAOP_PWM_FB2>,
			<&pericfg_ao_clk CLK_PERAOP_PWM_FB3>,
			<&pericfg_ao_clk CLK_PERAOP_PWM_FB4>,
			<&pericfg_ao_clk CLK_PERAOP_DISP_PWM0>,
			<&pericfg_ao_clk CLK_PERAOP_DISP_PWM1>,
			<&pericfg_ao_clk CLK_PERAOP_SPI0_B>,
			<&pericfg_ao_clk CLK_PERAOP_SPI1_B>,
			<&pericfg_ao_clk CLK_PERAOP_SPI2_B>,
			<&pericfg_ao_clk CLK_PERAOP_SPI3_B>,
			<&pericfg_ao_clk CLK_PERAOP_SPI4_B>,
			<&pericfg_ao_clk CLK_PERAOP_SPI5_B>,
			<&pericfg_ao_clk CLK_PERAOP_SPI6_B>,
			<&pericfg_ao_clk CLK_PERAOP_SPI7_B>,
			<&pericfg_ao_clk CLK_PERAOP_DMA_B>,
			<&pericfg_ao_clk CLK_PERAOP_SSUSB0_FRMCNT>,
			<&pericfg_ao_clk CLK_PERAOP_SSUSB1_FRMCNT>,
			<&pericfg_ao_clk CLK_PERAOP_MSDC1>,
			<&pericfg_ao_clk CLK_PERAOP_MSDC1_F>,
			<&pericfg_ao_clk CLK_PERAOP_MSDC1_H>,
			<&pericfg_ao_clk CLK_PERAOP_MSDC2>,
			<&pericfg_ao_clk CLK_PERAOP_MSDC2_F>,
			<&pericfg_ao_clk CLK_PERAOP_MSDC2_H>,
			<&pericfg_ao_clk CLK_PERAOP_AUDIO_SLV>,
			<&pericfg_ao_clk CLK_PERAOP_AUDIO_MST>,
			<&pericfg_ao_clk CLK_PERAOP_AUDIO_INTBUS>,
			<&pericfg_ao_clk CLK_PERAOP_AUDIO_ENGEN1>,
			<&pericfg_ao_clk CLK_PERAOP_AUDIO_ENGEN2>,
			<&pericfg_ao_clk CLK_PERAOP_AUDIO_TDMOUT_B>,
			<&pericfg_ao_clk CLK_PERAOP_AUDIO_H_AUD>;
	};

	disable-unused-clk-infracfg-ao@95 {
		compatible = "mediatek,clk-disable-unused";
		reg = <0x95>;
		clocks =
			<&infracfg_ao_clk CLK_IFRAO_DPMAIF_MAIN>,
			<&infracfg_ao_clk CLK_IFRAO_RG_MMW_DPMAIF26M>,
			<&infracfg_ao_clk CLK_IFRAO_RG_SOCSYS_FATB>,
			<&infracfg_ao_clk CLK_IFRAO_RG_SOCSYS_SDF>;
	};

	disable-unused-clk-vlp-cksys@96 {
		compatible = "mediatek,clk-disable-unused";
		reg = <0x96>;
		clocks =
			<&vlp_cksys_clk CLK_VLP_CK_SCP_SEL>,
			<&vlp_cksys_clk CLK_VLP_CK_CAMTG0_SEL>,
			<&vlp_cksys_clk CLK_VLP_CK_IPS_SEL>;
	};

	disable-unused-clk-topckgen@97 {
		compatible = "mediatek,clk-disable-unused";
		reg = <0x97>;
		clocks =
			<&topckgen_clk CLK_TOP_APLL12_CK_DIV_I2SIN0>,
			<&topckgen_clk CLK_TOP_APLL12_CK_DIV_I2SIN1>,
			<&topckgen_clk CLK_TOP_APLL12_CK_DIV_I2SIN2>,
			<&topckgen_clk CLK_TOP_APLL12_CK_DIV_I2SIN3>,
			<&topckgen_clk CLK_TOP_APLL12_CK_DIV_I2SIN4>,
			<&topckgen_clk CLK_TOP_APLL12_CK_DIV_I2SIN6>,
			<&topckgen_clk CLK_TOP_APLL12_CK_DIV_I2SOUT0>,
			<&topckgen_clk CLK_TOP_APLL12_CK_DIV_I2SOUT1>,
			<&topckgen_clk CLK_TOP_APLL12_CK_DIV_I2SOUT2>,
			<&topckgen_clk CLK_TOP_APLL12_CK_DIV_I2SOUT3>,
			<&topckgen_clk CLK_TOP_APLL12_CK_DIV_I2SOUT4>,
			<&topckgen_clk CLK_TOP_APLL12_CK_DIV_I2SOUT6>,
			<&topckgen_clk CLK_TOP_APLL12_CK_DIV_FMI2S>,
			<&topckgen_clk CLK_TOP_APLL12_CK_DIV_TDMOUT_M>,
			<&topckgen_clk CLK_TOP_APLL12_CK_DIV_TDMOUT_B>,
			<&topckgen_clk CLK_TOP_DSP_SEL>,
			<&topckgen_clk CLK_TOP_SPI0_BCLK_SEL>,
			<&topckgen_clk CLK_TOP_SPI1_BCLK_SEL>,
			<&topckgen_clk CLK_TOP_SPI2_BCLK_SEL>,
			<&topckgen_clk CLK_TOP_SPI3_BCLK_SEL>,
			<&topckgen_clk CLK_TOP_SPI4_BCLK_SEL>,
			<&topckgen_clk CLK_TOP_SPI5_BCLK_SEL>,
			<&topckgen_clk CLK_TOP_SPI6_BCLK_SEL>,
			<&topckgen_clk CLK_TOP_SPI7_BCLK_SEL>,
			<&topckgen_clk CLK_TOP_MSDC_MACRO_1P_SEL>,
			<&topckgen_clk CLK_TOP_MSDC_MACRO_2P_SEL>,
			<&topckgen_clk CLK_TOP_MSDC30_1_SEL>,
			<&topckgen_clk CLK_TOP_MSDC30_2_SEL>,
			<&topckgen_clk CLK_TOP_AUD_INTBUS_SEL>,
			<&topckgen_clk CLK_TOP_DISP_PWM_SEL>,
			<&topckgen_clk CLK_TOP_USB_TOP_SEL>,
			<&topckgen_clk CLK_TOP_USB_XHCI_SEL>,
			<&topckgen_clk CLK_TOP_USB_TOP_1P_SEL>,
			<&topckgen_clk CLK_TOP_USB_XHCI_1P_SEL>,
			<&topckgen_clk CLK_TOP_I2C_SEL>,
			<&topckgen_clk CLK_TOP_AUD_ENGEN1_SEL>,
			<&topckgen_clk CLK_TOP_AUD_ENGEN2_SEL>,
			<&topckgen_clk CLK_TOP_PEXTP_MBIST_SEL>,
			<&topckgen_clk CLK_TOP_AUD_1_SEL>,
			<&topckgen_clk CLK_TOP_AUD_2_SEL>,
			<&topckgen_clk CLK_TOP_AUDIO_H_SEL>,
			<&topckgen_clk CLK_TOP_ADSP_SEL>,
			<&topckgen_clk CLK_TOP_ADSP_UARTHUB_BCLK_SEL>,
			<&topckgen_clk CLK_TOP_DPMAIF_MAIN_SEL>,
			<&topckgen_clk CLK_TOP_PWM_SEL>,
			<&topckgen_clk CLK_TOP_SFLASH_SEL>,
			<&topckgen_clk CLK_TOP_IPSEAST_SEL>,
			<&topckgen_clk CLK_TOP_IPSWEST_SEL>,
			<&topckgen_clk CLK_TOP_TL_SEL>,
			<&topckgen_clk CLK_TOP_EMI_INTERFACE_546_SEL>,
			<&topckgen_clk CLK_TOP_SDF_SEL>,
			<&topckgen_clk CLK_TOP_UARTHUB_BCLK_SEL>,
			<&topckgen_clk CLK_TOP_SSR_SEJ_SEL>,
			<&topckgen_clk CLK_TOP_APLL_I2SIN0_MCK_SEL>,
			<&topckgen_clk CLK_TOP_APLL_I2SIN1_MCK_SEL>,
			<&topckgen_clk CLK_TOP_APLL_I2SIN2_MCK_SEL>,
			<&topckgen_clk CLK_TOP_APLL_I2SIN3_MCK_SEL>,
			<&topckgen_clk CLK_TOP_APLL_I2SIN4_MCK_SEL>,
			<&topckgen_clk CLK_TOP_APLL_I2SIN6_MCK_SEL>,
			<&topckgen_clk CLK_TOP_APLL_I2SOUT0_MCK_SEL>,
			<&topckgen_clk CLK_TOP_APLL_I2SOUT1_MCK_SEL>,
			<&topckgen_clk CLK_TOP_APLL_I2SOUT2_MCK_SEL>,
			<&topckgen_clk CLK_TOP_APLL_I2SOUT3_MCK_SEL>,
			<&topckgen_clk CLK_TOP_APLL_I2SOUT4_MCK_SEL>,
			<&topckgen_clk CLK_TOP_APLL_I2SOUT6_MCK_SEL>,
			<&topckgen_clk CLK_TOP_APLL_FMI2S_MCK_SEL>,
			<&topckgen_clk CLK_TOP_APLL_TDMOUT_MCK_SEL>,
			<&topckgen_clk CLK_TOP_CAMTG1_SEL>,
			<&topckgen_clk CLK_TOP_CAMTG2_SEL>,
			<&topckgen_clk CLK_TOP_CAMTG3_SEL>,
			<&topckgen_clk CLK_TOP_CAMTG4_SEL>,
			<&topckgen_clk CLK_TOP_CAMTG5_SEL>,
			<&topckgen_clk CLK_TOP_CAMTG6_SEL>,
			<&topckgen_clk CLK_TOP_CAMTG7_SEL>,
			<&topckgen_clk CLK_TOP_SENINF0_SEL>,
			<&topckgen_clk CLK_TOP_SENINF1_SEL>,
			<&topckgen_clk CLK_TOP_SENINF2_SEL>,
			<&topckgen_clk CLK_TOP_SENINF3_SEL>,
			<&topckgen_clk CLK_TOP_SENINF4_SEL>,
			<&topckgen_clk CLK_TOP_SENINF5_SEL>,
			<&topckgen_clk CLK_TOP_CCU_AHB_SEL>,
			<&topckgen_clk CLK_TOP_IMG1_SEL>,
			<&topckgen_clk CLK_TOP_IPE_SEL>,
			<&topckgen_clk CLK_TOP_CAM_SEL>,
			<&topckgen_clk CLK_TOP_CAMTM_SEL>,
			<&topckgen_clk CLK_TOP_DPE_SEL>,
			<&topckgen_clk CLK_TOP_VDEC_SEL>,
			<&topckgen_clk CLK_TOP_CCUSYS_SEL>,
			<&topckgen_clk CLK_TOP_CCUTM_SEL>,
			<&topckgen_clk CLK_TOP_VENC_SEL>,
			<&topckgen_clk CLK_TOP_DP_CORE_SEL>,
			<&topckgen_clk CLK_TOP_DP_SEL>,
			<&topckgen_clk CLK_TOP_DISP_SEL>,
			<&topckgen_clk CLK_TOP_MDP_SEL>,
			<&topckgen_clk CLK_TOP_MMINFRA_SEL>;
	};

	disable-unused-clk-apmixedsys@98 {
		compatible = "mediatek,clk-disable-unused";
		reg = <0x98>;
		clocks =
			<&apmixedsys_clk CLK_APMIXED_MAINPLL>,
			<&apmixedsys_clk CLK_APMIXED_UNIVPLL>,
			<&apmixedsys_clk CLK_APMIXED_MSDCPLL>,
			<&apmixedsys_clk CLK_APMIXED_MMPLL>,
			<&apmixedsys_clk CLK_APMIXED_ADSPPLL>,
			<&apmixedsys_clk CLK_APMIXED_APLL1>,
			<&apmixedsys_clk CLK_APMIXED_APLL2>,
			<&apmixedsys_clk CLK_APMIXED_EMIPLL>,
			<&apmixedsys_clk CLK_APMIXED_EMIPLL2>,
			<&apmixedsys_clk CLK_APMIXED_MAINPLL2>,
			<&apmixedsys_clk CLK_APMIXED_UNIVPLL2>,
			<&apmixedsys_clk CLK_APMIXED_MMPLL2>,
			<&apmixedsys_clk CLK_APMIXED_TVDPLL>,
			<&apmixedsys_clk CLK_APMIXED_IMGPLL>;
	};

	disable-unused-clk-ccipll-pll-ctrl@99 {
		compatible = "mediatek,clk-disable-unused";
		reg = <0x99>;
		clocks =
			<&ccipll_pll_ctrl_clk CLK_CCIPLL>;
	};

	disable-unused-clk-armpll-ll-pll-ctrl@9a {
		compatible = "mediatek,clk-disable-unused";
		reg = <0x9a>;
		clocks =
			<&armpll_ll_pll_ctrl_clk CLK_CPU_LL_ARMPLL_LL>;
	};

	disable-unused-clk-armpll-bl-pll-ctrl@9b {
		compatible = "mediatek,clk-disable-unused";
		reg = <0x9b>;
		clocks =
			<&armpll_bl_pll_ctrl_clk CLK_CPU_BL_ARMPLL_BL>;
	};

	disable-unused-clk-armpll-b-pll-ctrl@9c {
		compatible = "mediatek,clk-disable-unused";
		reg = <0x9c>;
		clocks =
			<&armpll_b_pll_ctrl_clk CLK_CPU_B_ARMPLL_B>;
	};

	disable-unused-clk-ptppll-pll-ctrl@9d {
		compatible = "mediatek,clk-disable-unused";
		reg = <0x9d>;
		clocks =
			<&ptppll_pll_ctrl_clk CLK_PTPPLL>;
	};

	disable-unused-pd-peri-usb0@9e {
		compatible = "mediatek,scpsys-disable-unused";
		reg = <0x9e>;
		power-domains = <&scpsys MT6989_POWER_DOMAIN_PERI_USB0>;
	};

	disable-unused-pd-pextp-mac0@9f {
		compatible = "mediatek,scpsys-disable-unused";
		reg = <0x9f>;
		power-domains = <&scpsys MT6989_POWER_DOMAIN_PEXTP_MAC0>;
	};

	disable-unused-pd-pextp-mac1@a0 {
		compatible = "mediatek,scpsys-disable-unused";
		reg = <0xa0>;
		power-domains = <&scpsys MT6989_POWER_DOMAIN_PEXTP_MAC1>;
	};

	disable-unused-pd-pextp-phy0@a1 {
		compatible = "mediatek,scpsys-disable-unused";
		reg = <0xa1>;
		power-domains = <&scpsys MT6989_POWER_DOMAIN_PEXTP_PHY0>;
	};

	disable-unused-pd-pextp-phy1@a2 {
		compatible = "mediatek,scpsys-disable-unused";
		reg = <0xa2>;
		power-domains = <&scpsys MT6989_POWER_DOMAIN_PEXTP_PHY1>;
	};

	disable-unused-pd-audio@a3 {
		compatible = "mediatek,scpsys-disable-unused";
		reg = <0xa3>;
		power-domains = <&scpsys MT6989_POWER_DOMAIN_AUDIO>;
	};

	disable-unused-pd-adsp-top-dormant@a4 {
		compatible = "mediatek,scpsys-disable-unused";
		reg = <0xa4>;
		power-domains = <&scpsys MT6989_POWER_DOMAIN_ADSP_TOP_DORMANT>;
	};

	disable-unused-pd-adsp-ao@a5 {
		compatible = "mediatek,scpsys-disable-unused";
		reg = <0xa5>;
		power-domains = <&scpsys MT6989_POWER_DOMAIN_ADSP_AO>;
	};

	disable-unused-pd-mm-infra@a6 {
		compatible = "mediatek,scpsys-disable-unused";
		reg = <0xa6>;
		power-domains = <&scpsys MT6989_POWER_DOMAIN_MM_INFRA>;
	};

	disable-unused-pd-ssrsys@a7 {
		compatible = "mediatek,scpsys-disable-unused";
		reg = <0xa7>;
		power-domains = <&scpsys MT6989_POWER_DOMAIN_SSR>;
	};

	disable-unused-pd-isp-traw@a8 {
		compatible = "mediatek,scpsys-disable-unused";
		reg = <0xa8>;
		power-domains = <&scpsys MT6989_POWER_DOMAIN_ISP_TRAW>;
	};

	disable-unused-pd-isp-dip1@a9 {
		compatible = "mediatek,scpsys-disable-unused";
		reg = <0xa9>;
		power-domains = <&scpsys MT6989_POWER_DOMAIN_ISP_DIP1>;
	};

	disable-unused-pd-isp-main@aa {
		compatible = "mediatek,scpsys-disable-unused";
		reg = <0xaa>;
		power-domains = <&scpsys MT6989_POWER_DOMAIN_ISP_MAIN>;
	};

	disable-unused-pd-isp-vcore@ab {
		compatible = "mediatek,scpsys-disable-unused";
		reg = <0xab>;
		power-domains = <&scpsys MT6989_POWER_DOMAIN_ISP_VCORE>;
	};

	disable-unused-pd-vde0@ac {
		compatible = "mediatek,scpsys-disable-unused";
		reg = <0xac>;
		power-domains = <&scpsys MT6989_POWER_DOMAIN_VDE0>;
	};

	disable-unused-pd-vde1@ad {
		compatible = "mediatek,scpsys-disable-unused";
		reg = <0xad>;
		power-domains = <&scpsys MT6989_POWER_DOMAIN_VDE1>;
	};

	disable-unused-pd-vde-vcore0@ae {
		compatible = "mediatek,scpsys-disable-unused";
		reg = <0xae>;
		power-domains = <&scpsys MT6989_POWER_DOMAIN_VDE_VCORE0>;
	};

	disable-unused-pd-vde-vcore1@af {
		compatible = "mediatek,scpsys-disable-unused";
		reg = <0xaf>;
		power-domains = <&scpsys MT6989_POWER_DOMAIN_VDE_VCORE1>;
	};

	disable-unused-pd-ven0@b0 {
		compatible = "mediatek,scpsys-disable-unused";
		reg = <0xb0>;
		power-domains = <&scpsys MT6989_POWER_DOMAIN_VEN0>;
	};

	disable-unused-pd-ven1@b1 {
		compatible = "mediatek,scpsys-disable-unused";
		reg = <0xb1>;
		power-domains = <&scpsys MT6989_POWER_DOMAIN_VEN1>;
	};

	disable-unused-pd-ven2@b2 {
		compatible = "mediatek,scpsys-disable-unused";
		reg = <0xb2>;
		power-domains = <&scpsys MT6989_POWER_DOMAIN_VEN2>;
	};

	disable-unused-pd-cam-mraw@b3 {
		compatible = "mediatek,scpsys-disable-unused";
		reg = <0xb3>;
		power-domains = <&scpsys MT6989_POWER_DOMAIN_CAM_MRAW>;
	};

	disable-unused-pd-cam-suba@b4 {
		compatible = "mediatek,scpsys-disable-unused";
		reg = <0xb4>;
		power-domains = <&scpsys MT6989_POWER_DOMAIN_CAM_SUBA>;
	};

	disable-unused-pd-cam-subb@b5 {
		compatible = "mediatek,scpsys-disable-unused";
		reg = <0xb5>;
		power-domains = <&scpsys MT6989_POWER_DOMAIN_CAM_SUBB>;
	};

	disable-unused-pd-cam-subc@b6 {
		compatible = "mediatek,scpsys-disable-unused";
		reg = <0xb6>;
		power-domains = <&scpsys MT6989_POWER_DOMAIN_CAM_SUBC>;
	};

	disable-unused-pd-cam-main@b7 {
		compatible = "mediatek,scpsys-disable-unused";
		reg = <0xb7>;
		power-domains = <&scpsys MT6989_POWER_DOMAIN_CAM_MAIN>;
	};

	disable-unused-pd-cam-vcore@b8 {
		compatible = "mediatek,scpsys-disable-unused";
		reg = <0xb8>;
		power-domains = <&scpsys MT6989_POWER_DOMAIN_CAM_VCORE>;
	};

	disable-unused-pd-cam-ccu@b9 {
		compatible = "mediatek,scpsys-disable-unused";
		reg = <0xb9>;
		power-domains = <&scpsys MT6989_POWER_DOMAIN_CAM_CCU>;
	};

	disable-unused-pd-cam-ccu-ao@ba {
		compatible = "mediatek,scpsys-disable-unused";
		reg = <0xba>;
		power-domains = <&scpsys MT6989_POWER_DOMAIN_CAM_CCU_AO>;
	};

	disable-unused-pd-disp-vcore@bb {
		compatible = "mediatek,scpsys-disable-unused";
		reg = <0xbb>;
		power-domains = <&scpsys MT6989_POWER_DOMAIN_DISP_VCORE>;
	};

	disable-unused-pd-mml0-shutdown@bc {
		compatible = "mediatek,scpsys-disable-unused";
		reg = <0xbc>;
		power-domains = <&scpsys MT6989_POWER_DOMAIN_MML0_SHUTDOWN>;
	};

	disable-unused-pd-mml1-shutdown@bd {
		compatible = "mediatek,scpsys-disable-unused";
		reg = <0xbd>;
		power-domains = <&scpsys MT6989_POWER_DOMAIN_MML1_SHUTDOWN>;
	};

	disable-unused-pd-dis0-shutdown@be {
		compatible = "mediatek,scpsys-disable-unused";
		reg = <0xbe>;
		power-domains = <&scpsys MT6989_POWER_DOMAIN_DIS0_SHUTDOWN>;
	};

	disable-unused-pd-dis1-shutdown@bf {
		compatible = "mediatek,scpsys-disable-unused";
		reg = <0xbf>;
		power-domains = <&scpsys MT6989_POWER_DOMAIN_DIS1_SHUTDOWN>;
	};

	disable-unused-pd-ovl0-shutdown@c0 {
		compatible = "mediatek,scpsys-disable-unused";
		reg = <0xc0>;
		power-domains = <&scpsys MT6989_POWER_DOMAIN_OVL0_SHUTDOWN>;
	};

	disable-unused-pd-ovl1-shutdown@c1 {
		compatible = "mediatek,scpsys-disable-unused";
		reg = <0xc1>;
		power-domains = <&scpsys MT6989_POWER_DOMAIN_OVL1_SHUTDOWN>;
	};

	disable-unused-pd-dp-tx@c2 {
		compatible = "mediatek,scpsys-disable-unused";
		reg = <0xc2>;
		power-domains = <&scpsys MT6989_POWER_DOMAIN_DP_TX>;
	};

	disable-unused-pd-csi-rx@c3 {
		compatible = "mediatek,scpsys-disable-unused";
		reg = <0xc3>;
		power-domains = <&scpsys MT6989_POWER_DOMAIN_CSI_RX>;
	};
};
